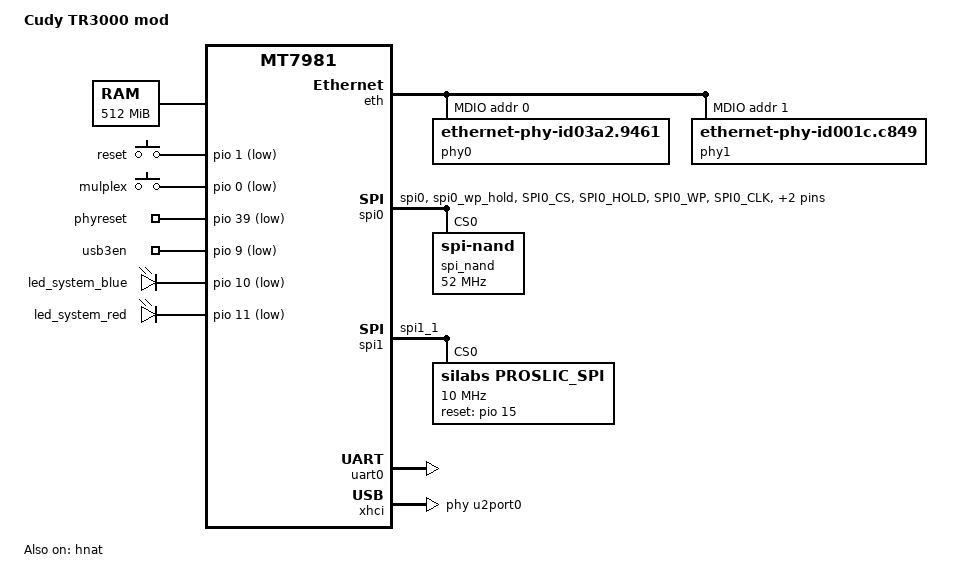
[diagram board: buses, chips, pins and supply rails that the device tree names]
/dts-v1/;
#include "mt7981.dtsi"
/ {
	model = "Cudy TR3000 mod";
	compatible = "Cudy TR3000","mediatek,mt7981";
		
	aliases {
		led-boot = &led_system_blue;
		led-failsafe = &led_system_red;
		led-running = &led_system_blue;
		led-upgrade = &led_system_red;
	};
	
	chosen {
		bootargs = "console=ttyS0,115200n1 loglevel=8 \
				earlycon=uart8250,mmio32,0x11002000";
	};

	memory {
		// fpga ddr2: 128MB*2
		reg = <0 0x40000000 0 0x20000000>;
	};

	gpio-keys {
		compatible = "gpio-keys";
		poll-interval = <20>;

		reset {
			label = "reset";
			linux,code = <KEY_RESTART>;
			gpios = <&pio 1 GPIO_ACTIVE_LOW>;
		};
		mulplex {
			label = "mulplex";
			gpios = <&pio 0 GPIO_ACTIVE_LOW>;
			linux,code = <KEY_SETUP>;
		};
	};

	gpio_export {
		compatible = "gpio-export";
		#size-cells = <0>;

		phyreset {
			gpio-export,name = "phyreset";
			gpio-export,output = <1>;
			gpios = <&pio 39 GPIO_ACTIVE_LOW>;
		};

		usb3en {
			gpio-export,name = "usb3en";
			gpio-export,output = <1>;
			gpios = <&pio 9 GPIO_ACTIVE_LOW>;
		};
	};

	leds {
		compatible = "gpio-leds";
		
		led_system_blue: system_blue {
			label = "led_system_blue";
			gpios = <&pio 10 GPIO_ACTIVE_LOW>;
		};

		led_system_red: system_red {
			label = "led_system_red";
			gpios = <&pio 11 GPIO_ACTIVE_LOW>;
		};
	};


	nmbm_spim_nand {
		compatible = "generic,nmbm";
		#address-cells = <1>;
		#size-cells = <1>;

		lower-mtd-device = <&spi_nand>;
		forced-create;

		partitions {
			compatible = "fixed-partitions";
			#address-cells = <1>;
			#size-cells = <1>;

			partition@0 {
				label = "BL2";
				reg = <0x00000 0x0100000>;
				read-only;
			};

			partition@100000 {
				label = "u-boot-env";
				reg = <0x0100000 0x0080000>;
			};

			partition@180000 {
				label = "Factory";
				reg = <0x180000 0x0200000>;
			};
			
			bdinfo: partition@380000 {
				label = "bdinfo";
				reg = <0x380000 0x0040000>;
			};

			partition@3C0000 {
				label = "FIP";
				reg = <0x3C0000 0x0200000>;
			};

			partition@5C0000 {
				label = "ubi";
				reg = <0x5C0000 0x7000000>;
			};
		};
	};

};


&eth {
    status = "okay";
    lower-mtd-name = "bdinfo";

    gmac0: mac@0 {
		compatible = "mediatek,eth-mac";
		reg = <0>;
		phy-mode = "2500base-x";
		phy-handle = <&phy1>;

        fixed-link {
			speed = <2500>;
			full-duplex;
			pause;
        };

    };

	gmac1: mac@1 {
		compatible = "mediatek,eth-mac";
		reg = <1>;
		mtd-mac-address = <&bdinfo 0xDE00>;
		phy-mode = "gmii";
		phy-handle = <&phy0>;
	};

    mdio: mdio-bus {
        #address-cells = <1>;
        #size-cells = <0>;

		phy0: phy@0 {
			compatible = "ethernet-phy-id03a2.9461";
			reg = <0>;
			phy-mode = "gmii";
			nvmem-cells = <&phy_calibration>;
			nvmem-cell-names = "phy-cal-data";
		};

		phy1: phy@1 {
			compatible = "ethernet-phy-id001c.c849";
			reg = <1>;
			phy-mode = "2500base-x";
		};
    };
};

&hnat {
	mtketh-wan = "eth0";
	mtketh-lan = "eth1";
	mtketh-ppd = "eth1";
	mtketh-max-gmac = <2>;
	mtketh-lan-gmac = <2>;
	mtketh-wan-gmac = <1>;
	status = "okay";
};

&spi0 {
	pinctrl-names = "default";
	pinctrl-0 = <&spi0_flash_pins>;
	status = "okay";

	spi_nand: spi_nand@0 {
		compatible = "spi-nand";
		#address-cells = <1>;
		#size-cells = <1>;
		reg = <0>;

		spi-max-frequency = <52000000>;
		spi-tx-bus-width = <4>;
		spi-rx-bus-width = <4>;
	};
};

&spi1 {
	pinctrl-names = "default";
	pinctrl-0 = <&spic_pins>;
	status = "okay";

	proslic_spi: proslic_spi@0 {
		compatible = "silabs,proslic_spi";
		reg = <0>;
		spi-max-frequency = <10000000>;
		spi-cpha = <1>;
		spi-cpol = <1>;
		channel_count = <1>;
		debug_level = <4>;       /* 1 = TRC, 2 = DBG, 4 = ERR */
		reset_gpio = <&pio 15 0>;
		ig,enable-spi = <1>;     /* 1: Enable, 0: Disable */
	};
};

&pio {
        pwm0_pin: pwm0-pin-g0 {
                mux {
                        function = "pwm";
                        groups = "pwm0_0";
                };
        };

        pwm1_pin: pwm1-pin-g0 {
                mux {
                        function = "pwm";
                        groups = "pwm1_0";
                };
        };

        pwm2_pin: pwm2-pin {
                mux {
                        function = "pwm";
                        groups = "pwm2";
                };
        };

	spi0_flash_pins: spi0-pins {
		mux {
			function = "spi";
			groups = "spi0", "spi0_wp_hold";
		};

		conf-pu {
			pins = "SPI0_CS", "SPI0_HOLD", "SPI0_WP";
			drive-strength = <MTK_DRIVE_8mA>;
			bias-pull-up = <MTK_PUPD_SET_R1R0_11>;
		};

		conf-pd {
			pins = "SPI0_CLK", "SPI0_MOSI", "SPI0_MISO";
			drive-strength = <MTK_DRIVE_8mA>;
			bias-pull-down = <MTK_PUPD_SET_R1R0_11>;
		};
	};

	spic_pins: spi1-pins {
		mux {
			function = "spi";
			groups = "spi1_1";
		};
	};

	uart1_pins: uart1-pins-g1 {
                mux {
                        function = "uart";
                        groups = "uart1_1";
                };
        };

	uart2_pins: uart2-pins-g1 {
		mux {
                        function = "uart";
                        groups = "uart2_1";
                };
        };
};

&uart0 {
	status = "okay";
};

&xhci {
	mediatek,u3p-dis-msk = <0x0>;
	phys = <&u2port0 PHY_TYPE_USB2>,
	       <&u3port0 PHY_TYPE_USB3>;
	status = "okay";
};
